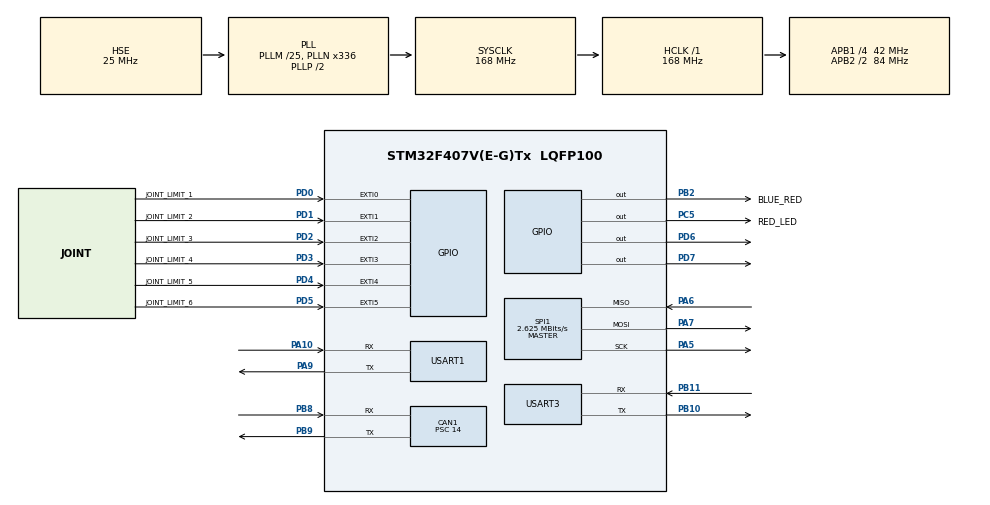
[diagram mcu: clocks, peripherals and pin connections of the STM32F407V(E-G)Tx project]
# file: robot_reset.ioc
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CAN1.AWUM=ENABLE
CAN1.BS1=CAN_BS1_4TQ
CAN1.CalculateBaudRate=499999
CAN1.CalculateTimeBit=2000
CAN1.CalculateTimeQuantum=333.33333333333337
CAN1.Prescaler=14
Dma.Request0=USART3_RX
Dma.USART3_RX.0.Direction=DMA_PERIPH_TO_MEMORY
Dma.USART3_RX.0.FIFOMode=DMA_FIFOMODE_DISABLE
Dma.USART3_RX.0.Instance=DMA1_Stream1
Dma.USART3_RX.0.MemDataAlignment=DMA_MDATAALIGN_BYTE
Dma.USART3_RX.0.MemInc=DMA_MINC_ENABLE
Dma.USART3_RX.0.Mode=DMA_CIRCULAR
Dma.USART3_RX.0.PeriphDataAlignment=DMA_PDATAALIGN_BYTE
Dma.USART3_RX.0.PeriphInc=DMA_PINC_DISABLE
Dma.USART3_RX.0.Priority=DMA_PRIORITY_HIGH
FREERTOS.Tasks01=defaultTask,24,128,StartDefaultTask,Default,NULL,Dynamic,NULL,NULL
FREERTOS.configUSE_NEWLIB_REENTRANT=1
Mcu.Family=STM32F4
Mcu.Name=STM32F407V(E-G)Tx
Mcu.Package=LQFP100
NVIC.CAN1_RX0_IRQn=true\:5\:0\:false\:false\:true\:true\:true\:true\:true
NVIC.DMA1_Stream1_IRQn=true\:5\:0\:false\:false\:true\:true\:false\:true\:true
NVIC.EXTI0_IRQn=true\:5\:0\:false\:false\:true\:true\:true\:true\:true
NVIC.EXTI1_IRQn=true\:5\:0\:false\:false\:true\:true\:true\:true\:true
NVIC.EXTI2_IRQn=true\:5\:0\:false\:false\:true\:true\:true\:true\:true
NVIC.EXTI3_IRQn=true\:5\:0\:false\:false\:true\:true\:true\:true\:true
NVIC.EXTI4_IRQn=true\:5\:0\:false\:false\:true\:true\:true\:true\:true
NVIC.EXTI9_5_IRQn=true\:5\:0\:false\:false\:true\:true\:true\:true\:true
NVIC.PriorityGroup=NVIC_PRIORITYGROUP_4
NVIC.TIM6_DAC_IRQn=true\:15\:0\:false\:false\:true\:false\:false\:true\:true
NVIC.TimeBase=TIM6_DAC_IRQn
NVIC.TimeBaseIP=TIM6
NVIC.USART1_IRQn=true\:5\:0\:false\:false\:true\:true\:true\:true\:true
NVIC.USART3_IRQn=true\:5\:0\:false\:false\:true\:true\:true\:true\:true
PA10.Mode=Asynchronous
PA10.Signal=USART1_RX
PA13.Mode=Serial_Wire
PA13.Signal=SYS_JTMS-SWDIO
PA14.Mode=Serial_Wire
PA14.Signal=SYS_JTCK-SWCLK
PA5.Mode=Full_Duplex_Master
PA5.Signal=SPI1_SCK
PA6.Mode=Full_Duplex_Master
PA6.Signal=SPI1_MISO
PA7.Mode=Full_Duplex_Master
PA7.Signal=SPI1_MOSI
PA9.Mode=Asynchronous
PA9.Signal=USART1_TX
PB10.Mode=Asynchronous
PB10.Signal=USART3_TX
PB11.Mode=Asynchronous
PB11.Signal=USART3_RX
PB2.GPIO_Label=BLUE_RED
PB2.Signal=GPIO_Output
PB8.Mode=CAN_Activate
PB8.Signal=CAN1_RX
PB9.Mode=CAN_Activate
PB9.Signal=CAN1_TX
PC5.GPIO_Label=RED_LED
PC5.Signal=GPIO_Output
PD0.GPIO_Label=JOINT_LIMIT_1
PD0.GPIO_PuPd=GPIO_PULLUP
PD0.Signal=GPXTI0
PD1.GPIO_Label=JOINT_LIMIT_2
PD1.GPIO_PuPd=GPIO_PULLUP
PD1.Signal=GPXTI1
PD2.GPIO_Label=JOINT_LIMIT_3
PD2.GPIO_PuPd=GPIO_PULLUP
PD2.Signal=GPXTI2
PD3.GPIO_Label=JOINT_LIMIT_4
PD3.GPIO_PuPd=GPIO_PULLUP
PD3.Signal=GPXTI3
PD4.GPIO_Label=JOINT_LIMIT_5
PD4.GPIO_PuPd=GPIO_PULLUP
PD4.Signal=GPXTI4
PD5.GPIO_Label=JOINT_LIMIT_6
PD5.GPIO_PuPd=GPIO_PULLUP
PD5.Signal=GPXTI5
PD6.Signal=GPIO_Output
PD7.PinState=GPIO_PIN_SET
PD7.Signal=GPIO_Output
PH0-OSC_IN.Mode=HSE-External-Oscillator
PH0-OSC_IN.Signal=RCC_OSC_IN
PH1-OSC_OUT.Mode=HSE-External-Oscillator
PH1-OSC_OUT.Signal=RCC_OSC_OUT
ProjectManager.HeapSize=0x200
ProjectManager.StackSize=0x400
ProjectManager.TargetToolchain=STM32CubeIDE
RCC.48MHZClocksFreq_Value=42000000
RCC.AHBFreq_Value=168000000
RCC.APB1CLKDivider=RCC_HCLK_DIV4
RCC.APB1Freq_Value=42000000
RCC.APB1TimFreq_Value=84000000
RCC.APB2CLKDivider=RCC_HCLK_DIV2
RCC.APB2Freq_Value=84000000
RCC.APB2TimFreq_Value=168000000
RCC.CortexFreq_Value=168000000
RCC.HCLKFreq_Value=168000000
RCC.HSE_VALUE=25000000
RCC.HSI_VALUE=16000000
RCC.LSE_VALUE=32768
RCC.PLLM=25
RCC.PLLN=336
RCC.PLLQ=8
RCC.PLLSourceVirtual=RCC_PLLSOURCE_HSE
RCC.SYSCLKFreq_VALUE=168000000
RCC.SYSCLKSource=RCC_SYSCLKSOURCE_PLLCLK
RCC.VCOOutputFreq_Value=336000000
SPI1.BaudRatePrescaler=SPI_BAUDRATEPRESCALER_32
SPI1.CalculateBaudRate=2.625 MBits/s
SPI1.Direction=SPI_DIRECTION_2LINES
SPI1.Mode=SPI_MODE_MASTER
SPI1.VirtualType=VM_MASTER
USART1.VirtualMode=VM_ASYNC
USART3.VirtualMode=VM_ASYNC
VP_FREERTOS_VS_CMSIS_V2.Mode=CMSIS_V2
VP_RNG_VS_RNG.Mode=RNG_Activate
VP_SYS_VS_tim6.Mode=TIM6
board=custom

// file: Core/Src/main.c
/* USER CODE BEGIN Header */
/**
  ******************************************************************************
  * @file           : main.c
  * @brief          : Main program body
  ******************************************************************************
  * @attention
  *
  * Copyright (c) 2026 STMicroelectronics.
  * All rights reserved.
  *
  * This software is licensed under terms that can be found in the LICENSE file
  * in the root directory of this software component.
  * If no LICENSE file comes with this software, it is provided AS-IS.
  *
  ******************************************************************************
  */
/* USER CODE END Header */
#include "main.h"
#include "cmsis_os.h"
#include "can.h"
#include "dma.h"
#include "rng.h"
#include "spi.h"
#include "usart.h"
#include "gpio.h"

/* USER CODE BEGIN Includes */
#include "stdio.h"
/* USER CODE END Includes */

void SystemClock_Config(void);
void MX_FREERTOS_Init(void);

int main(void)
{

  /* MCU Configuration--------------------------------------------------------*/

  /* Reset of all peripherals, Initializes the Flash interface and the Systick. */
  HAL_Init();

  /* Configure the system clock */
  SystemClock_Config();

  /* Initialize all configured peripherals */
  MX_GPIO_Init();
  MX_DMA_Init();
  MX_CAN1_Init();
  MX_USART1_UART_Init();
  MX_USART3_UART_Init();
  MX_RNG_Init();
  MX_SPI1_Init();
  /* USER CODE BEGIN 2 */
// 1. 初始化 CAN 过滤器
USER_CAN_FILTER_Init();

// 2. 启动 CAN 控制器
  if (HAL_CAN_Start(&hcan1) != HAL_OK) {
      Error_Handler();
  }

  // 3. 使能 CAN 接收中断
  if (HAL_CAN_ActivateNotification(&hcan1, CAN_IT_RX_FIFO0_MSG_PENDING) != HAL_OK) {
      Error_Handler();
  }

  /* USER CODE END 2 */

  /* Init scheduler */
  osKernelInitialize();  /* Call init function for freertos objects (in cmsis_os2.c) */
  MX_FREERTOS_Init();

  /* Start scheduler */
  osKernelStart();

  /* We should never get here as control is now taken by the scheduler */

  /* Infinite loop */
  while (1)
  {

  }
}

void SystemClock_Config(void)
{
  RCC_OscInitTypeDef RCC_OscInitStruct = {0};
  RCC_ClkInitTypeDef RCC_ClkInitStruct = {0};

  /** Configure the main internal regulator output voltage
  */
  __HAL_RCC_PWR_CLK_ENABLE();
  __HAL_PWR_VOLTAGESCALING_CONFIG(PWR_REGULATOR_VOLTAGE_SCALE1);

  /** Initializes the RCC Oscillators according to the specified parameters
  * in the RCC_OscInitTypeDef structure.
  */
  RCC_OscInitStruct.OscillatorType = RCC_OSCILLATORTYPE_HSE;
  RCC_OscInitStruct.HSEState = RCC_HSE_ON;
  RCC_OscInitStruct.PLL.PLLState = RCC_PLL_ON;
  RCC_OscInitStruct.PLL.PLLSource = RCC_PLLSOURCE_HSE;
  RCC_OscInitStruct.PLL.PLLM = 25;
  RCC_OscInitStruct.PLL.PLLN = 336;
  RCC_OscInitStruct.PLL.PLLP = RCC_PLLP_DIV2;
  RCC_OscInitStruct.PLL.PLLQ = 8;
  if (HAL_RCC_OscConfig(&RCC_OscInitStruct) != HAL_OK)
  {
    Error_Handler();
  }

  /** Initializes the CPU, AHB and APB buses clocks
  */
  RCC_ClkInitStruct.ClockType = RCC_CLOCKTYPE_HCLK|RCC_CLOCKTYPE_SYSCLK
                              |RCC_CLOCKTYPE_PCLK1|RCC_CLOCKTYPE_PCLK2;
  RCC_ClkInitStruct.SYSCLKSource = RCC_SYSCLKSOURCE_PLLCLK;
  RCC_ClkInitStruct.AHBCLKDivider = RCC_SYSCLK_DIV1;
  RCC_ClkInitStruct.APB1CLKDivider = RCC_HCLK_DIV4;
  RCC_ClkInitStruct.APB2CLKDivider = RCC_HCLK_DIV2;

  if (HAL_RCC_ClockConfig(&RCC_ClkInitStruct, FLASH_LATENCY_5) != HAL_OK)
  {
    Error_Handler();
  }
}

void HAL_TIM_PeriodElapsedCallback(TIM_HandleTypeDef *htim)
{
  if (htim->Instance == TIM6)
  {
    HAL_IncTick();
  }
}

void Error_Handler(void)
{
  __disable_irq();
  while (1)
  {
  }
}

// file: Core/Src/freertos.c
/* USER CODE BEGIN Header */
/**
  ******************************************************************************
  * File Name          : freertos.c
  * Description        : Code for freertos applications
  ******************************************************************************
  * @attention
  *
  * Copyright (c) 2026 STMicroelectronics.
  * All rights reserved.
  *
  * This software is licensed under terms that can be found in the LICENSE file
  * in the root directory of this software component.
  * If no LICENSE file comes with this software, it is provided AS-IS.
  *
  ******************************************************************************
  */
/* USER CODE END Header */

#include "FreeRTOS.h"
#include "task.h"
#include "main.h"
#include "cmsis_os.h"

/* USER CODE BEGIN Includes */
#include "robot.h"
#include "usart.h"

/* USER CODE END Includes */

/* Definitions for defaultTask */
osThreadId_t defaultTaskHandle;
const osThreadAttr_t defaultTask_attributes = {
  .name = "defaultTask",
  .stack_size = 128 * 4,
  .priority = (osPriority_t) osPriorityNormal,
};

void StartDefaultTask(void *argument);

void MX_FREERTOS_Init(void); /* (MISRA C 2004 rule 8.1) */

void MX_FREERTOS_Init(void) {

  /* Create the thread(s) */
  /* creation of defaultTask */
  defaultTaskHandle = osThreadNew(StartDefaultTask, NULL, &defaultTask_attributes);

}

void StartDefaultTask(void *argument)
{
  /* USER CODE BEGIN StartDefaultTask */
  /* Infinite loop */
  robot_init();
  struct robot_event event = {0};
  event.type = ROBOT_SET_HOME_EVENT;
  xQueueSend(g_robot.event_queue, &event, 0);

  for(;;)
  {
    osDelay(1);
  }
  /* USER CODE END StartDefaultTask */
}
